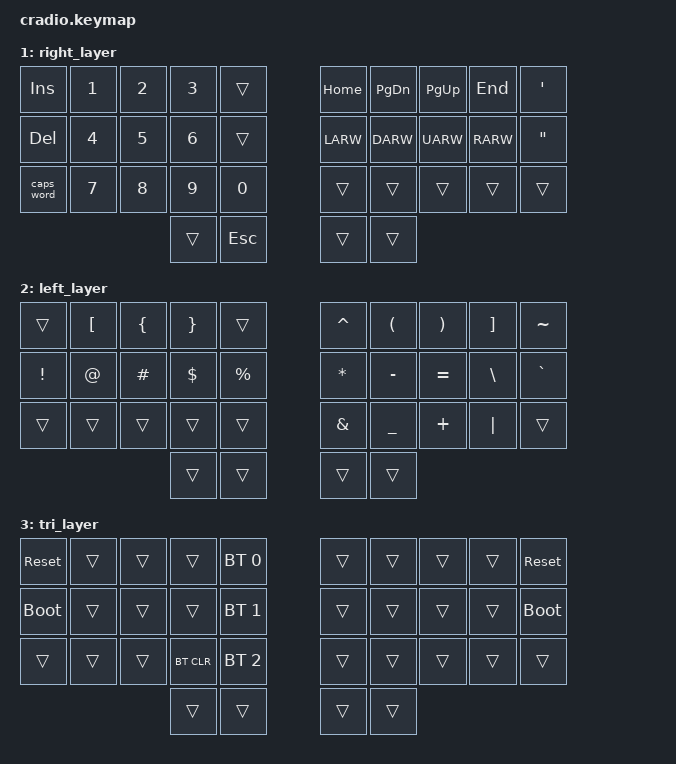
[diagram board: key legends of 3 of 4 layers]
// Copyright (c) 2022 The ZMK Contributors
// SPDX-License-Identifier: MIT

#include <behaviors.dtsi>
#include <dt-bindings/zmk/keys.h>
#include <dt-bindings/zmk/bt.h>

// Home row mods macro
#define HRML(k1,k2,k3,k4) &mt LSHFT k1  &mt LALT k2  &mt LCTRL k3  &mt LGUI k4
#define HRMR(k1,k2,k3,k4) &mt RGUI k1  &mt RCTRL k2  &mt RALT k3  &mt RSHFT k4

/ {
    behaviors {
        // legacy i guess
        ht: hold_tap {
            compatible = "zmk,behavior-hold-tap";
            #binding-cells = <2>;
            flavor = "tap-preferred";
            tapping-term-ms = <220>;
            quick-tap-ms = <150>;
            require-prior-idle-ms = <100>;
            bindings = <&kp>, <&kp>;
        };
    };

    conditional_layers {
        compatible = "zmk,conditional-layers";
        tri_layer {
            if-layers = <1 2>;
            then-layer = <3>;
        };
    };

    keymap {
        compatible = "zmk,keymap";
        // keypos_reference{
        //    bindings = <
        //╭──────────┬──────────┬──────────┬──────────┬──────────╮   ╭──────────┬──────────┬──────────┬──────────┬──────────╮
        //│  0       │  1       │  2       │  3       │  4       │   │  5       │  6       │  7       │  8       │  9       │
        //├──────────┼──────────┼──────────┼──────────┼──────────┤   ├──────────┼──────────┼──────────┼──────────┼──────────┤
        //│ 10       │ 11       │ 12       │ 13       │ 14       │   │ 15       │ 16       │ 17       │ 18       │ 19       │
        //├──────────┼──────────┼──────────┼──────────┼──────────┤   ├──────────┼──────────┼──────────┼──────────┼──────────┤
        //│ 20       │ 21       │ 22       │ 23       │ 24       │   │ 25       │ 26       │ 27       │ 28       │ 29       │
        //╰──────────┴──────────┴──────────┼──────────┼──────────┤   ├──────────┼──────────┼──────────┴──────────┴──────────╯
        //                                 │ 30       │ 31       │   │ 32       │ 33       │
        //                                 ╰──────────┴──────────╯   ╰──────────┴──────────╯
        //  >;
        //};

        default_layer {
            bindings = <
        //╭──────────┬──────────┬──────────┬──────────┬──────────╮   ╭──────────┬──────────┬──────────┬──────────┬──────────╮
        //│  Q       │  W       │  F       │  P       │  G       │   │  J       │  L       │  U       │  Y       │ ; :      │
            &kp Q      &kp W      &kp F      &kp P      &kp G          &kp J      &kp L      &kp U      &kp Y      &kp SEMI
        //├──────────┼──────────┼──────────┼──────────┼──────────┤   ├──────────┼──────────┼──────────┼──────────┼──────────┤
        //│  A       │  R       │  S       │  T       │  D       │   │  H       │  N       │  E       │  I       │  O       │
            HRML(A,        R,         S,         T)     &kp D          &kp H      HRMR(N,        E,         I,        O)
        //├──────────┼──────────┼──────────┼──────────┼──────────┤   ├──────────┼──────────┼──────────┼──────────┼──────────┤
        //│  Z       │  X       │  C       │  V       │  B       │   │  K       │  M       │ , <      │ . >      │ / ?      │
            &kp Z      &kp X      &kp C      &kp V      &kp B          &kp K      &kp M      &kp COMMA  &kp DOT    &kp FSLH
        //╰──────────┴──────────┴──────────┼──────────┼──────────┤   ├──────────┼──────────┼──────────┴──────────┴──────────╯
                                            &lt 2 TAB   &kp ENTER     &kp SPACE  &lt 1 BSPC
        //                                 ╰──────────┴──────────╯   ╰──────────┴──────────╯
            >;
        };

        right_layer {
            bindings = <
        //╭──────────┬──────────┬──────────┬──────────┬──────────╮   ╭──────────┬──────────┬──────────┬──────────┬──────────╮
        //│ INSERT   │  1       │  2       │  3       │          │   │ HOME     │ PAGE DN  │ PAGE UP  │ END      │ ' "      │
            &kp INS    &kp N1     &kp N2     &kp N3     &trans         &kp HOME   &kp PG_DN  &kp PG_UP  &kp END    &kp SQT
        //├──────────┼──────────┼──────────┼──────────┼──────────┤   ├──────────┼──────────┼──────────┼──────────┼──────────┤
        //│ DELETE   │  4       │  5       │  6       │          │   │ LEFT     │ DOWN     │ UP       │ RIGHT    │  "       │
            &kp DEL    &kp N4     &kp N5     &kp N6     &trans         &kp LARW   &kp DARW   &kp UARW   &kp RARW   &kp DQT
        //├──────────┼──────────┼──────────┼──────────┼──────────┤   ├──────────┼──────────┼──────────┼──────────┼──────────┤
        //│ CAPS     │  7       │  8       │  9       │  0       │   │          │          │          │          │          │
           &caps_word  &kp N7     &kp N8     &kp N9     &kp N0         &trans     &trans     &trans     &trans     &trans
        //╰──────────┴──────────┴──────────┼──────────┼──────────┤   ├──────────┼──────────┼──────────┴──────────┴──────────╯
                                             &trans     &kp ESC        &trans     &trans
        //                                 ╰──────────┴──────────╯   ╰──────────┴──────────╯
            >;
        };

        left_layer {
            bindings = <
        //╭──────────┬──────────┬──────────┬──────────┬──────────╮   ╭──────────┬──────────┬──────────┬──────────┬──────────╮
        //│          │  [       │  {       │  }       │          │   │  ^       │  (       │  )       │  ]       │  ~       │
            &trans     &kp LBKT   &kp LBRC   &kp RBRC   &trans         &kp CARET  &kp LPAR   &kp RPAR   &kp RBKT   &kp TILDE
        //├──────────┼──────────┼──────────┼──────────┼──────────┤   ├──────────┼──────────┼──────────┼──────────┼──────────┤
        //│  !       │  @       │  #       │  $       │  %       │   │  *       │  -       │  =       │  \       │  `       │
            &kp EXCL   &kp AT     &kp HASH   &kp DLLR   &kp PRCNT      &kp ASTRK  &kp MINUS  &kp EQUAL  &kp BSLH   &kp GRAVE
        //├──────────┼──────────┼──────────┼──────────┼──────────┤   ├──────────┼──────────┼──────────┼──────────┼──────────┤
        //│          │          │          │          │          │   │  &       │  _       │  +       │  │       │          │
            &trans     &trans     &trans     &trans     &trans         &kp AMPS   &kp UNDER  &kp PLUS   &kp PIPE   &trans
        //╰──────────┴──────────┴──────────┼──────────┼──────────┤   ├──────────┼──────────┼──────────┴──────────┴──────────╯
                                             &trans     &trans         &trans     &trans
        //                                 ╰──────────┴──────────╯   ╰──────────┴──────────╯
            >;
        };

        tri_layer {
            bindings = <
        //╭──────────┬──────────┬──────────┬──────────┬──────────╮   ╭──────────┬──────────┬──────────┬──────────┬──────────╮
        //│ RESET    │          │          │          │PROFILE 0 │   │          │          │          │          │  RESET   │
           &sys_reset  &trans     &trans     &trans    &bt BT_SEL 0    &trans     &trans     &trans     &trans    &sys_reset
        //├──────────┼──────────┼──────────┼──────────┼──────────┤   ├──────────┼──────────┼──────────┼──────────┼──────────┤
        //│BOOTLOADER│          │          │          │PROFILE 1 │   │          │          │          │          │BOOTLOADER│
          &bootloader  &trans     &trans     &trans    &bt BT_SEL 1    &trans     &trans     &trans     &trans    &bootloader
        //├──────────┼──────────┼──────────┼──────────┼──────────┤   ├──────────┼──────────┼──────────┼──────────┼──────────┤
        //│          │          │          │ CLEAR BT │PROFILE 2 │   │          │          │          │          │          │
            &trans     &trans     &trans    &bt BT_CLR &bt BT_SEL 2    &trans     &trans     &trans     &trans     &trans
        //╰──────────┴──────────┴──────────┼──────────┼──────────┤   ├──────────┼──────────┼──────────┴──────────┴──────────╯
                                             &trans     &trans         &trans     &trans
        //                                 ╰──────────┴──────────╯   ╰──────────┴──────────╯
            >;
        };
    };
};
